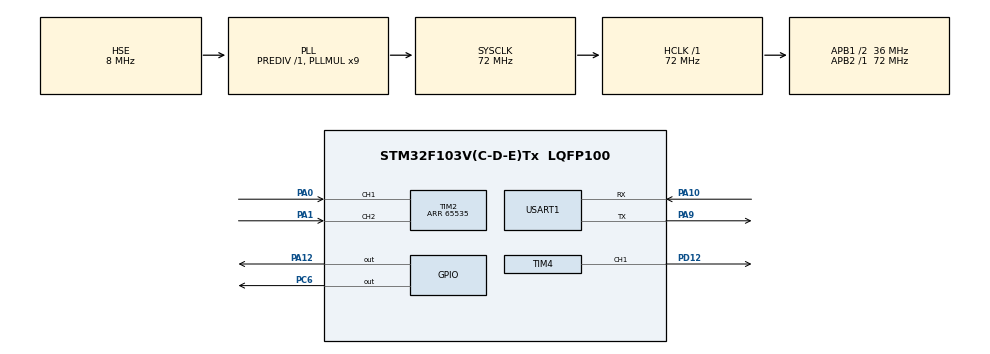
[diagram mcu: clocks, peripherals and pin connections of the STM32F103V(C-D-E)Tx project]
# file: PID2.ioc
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Mcu.Family=STM32F1
Mcu.Name=STM32F103V(C-D-E)Tx
Mcu.Package=LQFP100
NVIC.PriorityGroup=NVIC_PRIORITYGROUP_4
NVIC.TIM3_IRQn=true\:2\:0\:true\:false\:true\:true
NVIC.USART1_IRQn=true\:1\:0\:true\:false\:true\:true
OSC_IN.Mode=HSE-External-Oscillator
OSC_IN.Signal=RCC_OSC_IN
OSC_OUT.Mode=HSE-External-Oscillator
OSC_OUT.Signal=RCC_OSC_OUT
PA0-WKUP.Signal=S_TIM2_CH1_ETR
PA1.Signal=S_TIM2_CH2
PA10.Mode=Asynchronous
PA10.Signal=USART1_RX
PA12.GPIO_ModeDefaultOutputPP=GPIO_MODE_OUTPUT_OD
PA12.GPIO_Speed=GPIO_SPEED_FREQ_HIGH
PA12.PinState=GPIO_PIN_SET
PA12.Signal=GPIO_Output
PA13.Mode=JTAG_5_pins
PA13.Signal=SYS_JTMS-SWDIO
PA14.Mode=JTAG_5_pins
PA14.Signal=SYS_JTCK-SWCLK
PA15.Mode=JTAG_5_pins
PA15.Signal=SYS_JTDI
PA9.Mode=Asynchronous
PA9.Signal=USART1_TX
PB3.Mode=JTAG_5_pins
PB3.Signal=SYS_JTDO-TRACESWO
PB4.Mode=JTAG_5_pins
PB4.Signal=SYS_NJTRST
PC6.GPIO_Speed=GPIO_SPEED_FREQ_HIGH
PC6.PinState=GPIO_PIN_SET
PC6.Signal=GPIO_Output
PD12.Signal=S_TIM4_CH1
ProjectManager.HeapSize=0x200
ProjectManager.StackSize=0x400
ProjectManager.TargetToolchain=EWARM
RCC.AHBFreq_Value=72000000
RCC.APB1CLKDivider=RCC_HCLK_DIV2
RCC.APB1Freq_Value=36000000
RCC.APB1TimFreq_Value=72000000
RCC.APB2Freq_Value=72000000
RCC.APB2TimFreq_Value=72000000
RCC.HCLKFreq_Value=72000000
RCC.PLLMUL=RCC_PLL_MUL9
RCC.PLLSourceVirtual=RCC_PLLSOURCE_HSE
RCC.SYSCLKFreq_VALUE=72000000
RCC.SYSCLKSource=RCC_SYSCLKSOURCE_PLLCLK
RCC.USBFreq_Value=72000000
SH.S_TIM2_CH1_ETR.0=TIM2_CH1,Encoder_Interface
SH.S_TIM2_CH2.0=TIM2_CH2,Encoder_Interface
SH.S_TIM4_CH1.0=TIM4_CH1,PWM Generation1 CH1
TIM2.Period=65535
TIM3.CounterMode=TIM_COUNTERMODE_DOWN
TIM3.Period=59999
TIM3.Prescaler=35
TIM4.Channel-PWM\ Generation1\ CH1=TIM_CHANNEL_1
TIM4.Period=7199
TIM4.Pulse-PWM\ Generation1\ CH1=3600
USART1.VirtualMode=VM_ASYNC
VP_TIM3_VS_ClockSourceINT.Mode=Internal
VP_TIM4_VS_ClockSourceINT.Mode=Internal
board=PID2

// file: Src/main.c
/**
  ******************************************************************************
  * File Name          : main.c
  * Description        : Main program body
  ******************************************************************************
  ** This notice applies to any and all portions of this file
  * that are not between comment pairs USER CODE BEGIN and
  * USER CODE END. Other portions of this file, whether
  * inserted by the user or by software development tools
  * are owned by their respective copyright owners.
  *
  * COPYRIGHT(c) 2017 STMicroelectronics
  *
  * Redistribution and use in source and binary forms, with or without modification,
  * are permitted provided that the following conditions are met:
  *   1. Redistributions of source code must retain the above copyright notice,
  *      this list of conditions and the following disclaimer.
  *   2. Redistributions in binary form must reproduce the above copyright notice,
  *      this list of conditions and the following disclaimer in the documentation
  *      and/or other materials provided with the distribution.
  *   3. Neither the name of STMicroelectronics nor the names of its contributors
  *      may be used to endorse or promote products derived from this software
  *      without specific prior written permission.
  *
  * THIS SOFTWARE IS PROVIDED BY THE COPYRIGHT HOLDERS AND CONTRIBUTORS "AS IS"
  * AND ANY EXPRESS OR IMPLIED WARRANTIES, INCLUDING, BUT NOT LIMITED TO, THE
  * IMPLIED WARRANTIES OF MERCHANTABILITY AND FITNESS FOR A PARTICULAR PURPOSE ARE
  * DISCLAIMED. IN NO EVENT SHALL THE COPYRIGHT HOLDER OR CONTRIBUTORS BE LIABLE
  * FOR ANY DIRECT, INDIRECT, INCIDENTAL, SPECIAL, EXEMPLARY, OR CONSEQUENTIAL
  * DAMAGES (INCLUDING, BUT NOT LIMITED TO, PROCUREMENT OF SUBSTITUTE GOODS OR
  * SERVICES; LOSS OF USE, DATA, OR PROFITS; OR BUSINESS INTERRUPTION) HOWEVER
  * CAUSED AND ON ANY THEORY OF LIABILITY, WHETHER IN CONTRACT, STRICT LIABILITY,
  * OR TORT (INCLUDING NEGLIGENCE OR OTHERWISE) ARISING IN ANY WAY OUT OF THE USE
  * OF THIS SOFTWARE, EVEN IF ADVISED OF THE POSSIBILITY OF SUCH DAMAGE.
  *
  ******************************************************************************
  */

#include "main.h"
#include "stm32f1xx_hal.h"

TIM_HandleTypeDef htim2;
TIM_HandleTypeDef htim3;
TIM_HandleTypeDef htim4;

UART_HandleTypeDef huart1;

/* USER CODE BEGIN PV */
/* Private variables ---------------------------------------------------------*/

/* USER CODE END PV */

void SystemClock_Config(void);
static void MX_GPIO_Init(void);
static void MX_TIM2_Init(void);
static void MX_TIM4_Init(void);
static void MX_USART1_UART_Init(void);
static void MX_TIM3_Init(void);

void HAL_TIM_MspPostInit(TIM_HandleTypeDef *htim);

/* USER CODE BEGIN PFP */
/* Private function prototypes -----------------------------------------------*/

/* USER CODE END PFP */

int main(void)
{

  /* MCU Configuration----------------------------------------------------------*/

  /* Reset of all peripherals, Initializes the Flash interface and the Systick. */
  HAL_Init();

  /* Configure the system clock */
  SystemClock_Config();

  /* Initialize all configured peripherals */
  MX_GPIO_Init();
  MX_TIM2_Init();
  MX_TIM4_Init();
  MX_USART1_UART_Init();
  MX_TIM3_Init();

  /* USER CODE BEGIN 2 */
  HAL_TIM_Encoder_Start(&htim2, TIM_CHANNEL_ALL);//测速定时器
  HAL_TIM_Base_Start_IT(&htim3);//50ms pid 采样中断定时器
  HAL_TIM_PWM_Start(&htim4,TIM_CHANNEL_1);//10k pwm输出
  /* USER CODE END 2 */

  /* Infinite loop */
  while (1)
  {

  }

}

/** System Clock Configuration
*/
void SystemClock_Config(void)
{

  RCC_OscInitTypeDef RCC_OscInitStruct;
  RCC_ClkInitTypeDef RCC_ClkInitStruct;

    /**Initializes the CPU, AHB and APB busses clocks
    */
  RCC_OscInitStruct.OscillatorType = RCC_OSCILLATORTYPE_HSE;
  RCC_OscInitStruct.HSEState = RCC_HSE_ON;
  RCC_OscInitStruct.HSEPredivValue = RCC_HSE_PREDIV_DIV1;
  RCC_OscInitStruct.HSIState = RCC_HSI_ON;
  RCC_OscInitStruct.PLL.PLLState = RCC_PLL_ON;
  RCC_OscInitStruct.PLL.PLLSource = RCC_PLLSOURCE_HSE;
  RCC_OscInitStruct.PLL.PLLMUL = RCC_PLL_MUL9;
  if (HAL_RCC_OscConfig(&RCC_OscInitStruct) != HAL_OK)
  {
    _Error_Handler(__FILE__, __LINE__);
  }

    /**Initializes the CPU, AHB and APB busses clocks
    */
  RCC_ClkInitStruct.ClockType = RCC_CLOCKTYPE_HCLK|RCC_CLOCKTYPE_SYSCLK
                              |RCC_CLOCKTYPE_PCLK1|RCC_CLOCKTYPE_PCLK2;
  RCC_ClkInitStruct.SYSCLKSource = RCC_SYSCLKSOURCE_PLLCLK;
  RCC_ClkInitStruct.AHBCLKDivider = RCC_SYSCLK_DIV1;
  RCC_ClkInitStruct.APB1CLKDivider = RCC_HCLK_DIV2;
  RCC_ClkInitStruct.APB2CLKDivider = RCC_HCLK_DIV1;

  if (HAL_RCC_ClockConfig(&RCC_ClkInitStruct, FLASH_LATENCY_2) != HAL_OK)
  {
    _Error_Handler(__FILE__, __LINE__);
  }

    /**Configure the Systick interrupt time
    */
  HAL_SYSTICK_Config(HAL_RCC_GetHCLKFreq()/1000);

    /**Configure the Systick
    */
  HAL_SYSTICK_CLKSourceConfig(SYSTICK_CLKSOURCE_HCLK);

  /* SysTick_IRQn interrupt configuration */
  HAL_NVIC_SetPriority(SysTick_IRQn, 0, 0);
}

/* TIM2 init function */
static void MX_TIM2_Init(void)
{

  TIM_Encoder_InitTypeDef sConfig;
  TIM_MasterConfigTypeDef sMasterConfig;

  htim2.Instance = TIM2;
  htim2.Init.Prescaler = 0;
  htim2.Init.CounterMode = TIM_COUNTERMODE_UP;
  htim2.Init.Period = 65535;
  htim2.Init.ClockDivision = TIM_CLOCKDIVISION_DIV1;
  htim2.Init.AutoReloadPreload = TIM_AUTORELOAD_PRELOAD_DISABLE;
  sConfig.EncoderMode = TIM_ENCODERMODE_TI1;
  sConfig.IC1Polarity = TIM_ICPOLARITY_RISING;
  sConfig.IC1Selection = TIM_ICSELECTION_DIRECTTI;
  sConfig.IC1Prescaler = TIM_ICPSC_DIV1;
  sConfig.IC1Filter = 0;
  sConfig.IC2Polarity = TIM_ICPOLARITY_RISING;
  sConfig.IC2Selection = TIM_ICSELECTION_DIRECTTI;
  sConfig.IC2Prescaler = TIM_ICPSC_DIV1;
  sConfig.IC2Filter = 0;
  if (HAL_TIM_Encoder_Init(&htim2, &sConfig) != HAL_OK)
  {
    _Error_Handler(__FILE__, __LINE__);
  }

  sMasterConfig.MasterOutputTrigger = TIM_TRGO_RESET;
  sMasterConfig.MasterSlaveMode = TIM_MASTERSLAVEMODE_DISABLE;
  if (HAL_TIMEx_MasterConfigSynchronization(&htim2, &sMasterConfig) != HAL_OK)
  {
    _Error_Handler(__FILE__, __LINE__);
  }

}

/* TIM3 init function */
static void MX_TIM3_Init(void)
{

  TIM_ClockConfigTypeDef sClockSourceConfig;
  TIM_MasterConfigTypeDef sMasterConfig;

  htim3.Instance = TIM3;
  htim3.Init.Prescaler = 35;
  htim3.Init.CounterMode = TIM_COUNTERMODE_DOWN;
  htim3.Init.Period = 59999;
  htim3.Init.ClockDivision = TIM_CLOCKDIVISION_DIV1;
  htim3.Init.AutoReloadPreload = TIM_AUTORELOAD_PRELOAD_DISABLE;
  if (HAL_TIM_Base_Init(&htim3) != HAL_OK)
  {
    _Error_Handler(__FILE__, __LINE__);
  }

  sClockSourceConfig.ClockSource = TIM_CLOCKSOURCE_INTERNAL;
  if (HAL_TIM_ConfigClockSource(&htim3, &sClockSourceConfig) != HAL_OK)
  {
    _Error_Handler(__FILE__, __LINE__);
  }

  sMasterConfig.MasterOutputTrigger = TIM_TRGO_RESET;
  sMasterConfig.MasterSlaveMode = TIM_MASTERSLAVEMODE_DISABLE;
  if (HAL_TIMEx_MasterConfigSynchronization(&htim3, &sMasterConfig) != HAL_OK)
  {
    _Error_Handler(__FILE__, __LINE__);
  }

}

/* TIM4 init function */
static void MX_TIM4_Init(void)
{

  TIM_ClockConfigTypeDef sClockSourceConfig;
  TIM_MasterConfigTypeDef sMasterConfig;
  TIM_OC_InitTypeDef sConfigOC;

  htim4.Instance = TIM4;
  htim4.Init.Prescaler = 0;
  htim4.Init.CounterMode = TIM_COUNTERMODE_UP;
  htim4.Init.Period = 7199;
  htim4.Init.ClockDivision = TIM_CLOCKDIVISION_DIV1;
  htim4.Init.AutoReloadPreload = TIM_AUTORELOAD_PRELOAD_DISABLE;
  if (HAL_TIM_Base_Init(&htim4) != HAL_OK)
  {
    _Error_Handler(__FILE__, __LINE__);
  }

  sClockSourceConfig.ClockSource = TIM_CLOCKSOURCE_INTERNAL;
  if (HAL_TIM_ConfigClockSource(&htim4, &sClockSourceConfig) != HAL_OK)
  {
    _Error_Handler(__FILE__, __LINE__);
  }

  if (HAL_TIM_PWM_Init(&htim4) != HAL_OK)
  {
    _Error_Handler(__FILE__, __LINE__);
  }

  sMasterConfig.MasterOutputTrigger = TIM_TRGO_RESET;
  sMasterConfig.MasterSlaveMode = TIM_MASTERSLAVEMODE_DISABLE;
  if (HAL_TIMEx_MasterConfigSynchronization(&htim4, &sMasterConfig) != HAL_OK)
  {
    _Error_Handler(__FILE__, __LINE__);
  }

  sConfigOC.OCMode = TIM_OCMODE_PWM1;
  sConfigOC.Pulse = 3600;
  sConfigOC.OCPolarity = TIM_OCPOLARITY_HIGH;
  sConfigOC.OCFastMode = TIM_OCFAST_DISABLE;
  if (HAL_TIM_PWM_ConfigChannel(&htim4, &sConfigOC, TIM_CHANNEL_1) != HAL_OK)
  {
    _Error_Handler(__FILE__, __LINE__);
  }

  HAL_TIM_MspPostInit(&htim4);

}

/* USART1 init function */
static void MX_USART1_UART_Init(void)
{

  huart1.Instance = USART1;
  huart1.Init.BaudRate = 115200;
  huart1.Init.WordLength = UART_WORDLENGTH_8B;
  huart1.Init.StopBits = UART_STOPBITS_1;
  huart1.Init.Parity = UART_PARITY_NONE;
  huart1.Init.Mode = UART_MODE_TX_RX;
  huart1.Init.HwFlowCtl = UART_HWCONTROL_NONE;
  huart1.Init.OverSampling = UART_OVERSAMPLING_16;
  if (HAL_UART_Init(&huart1) != HAL_OK)
  {
    _Error_Handler(__FILE__, __LINE__);
  }

}

/** Configure pins as
        * Analog
        * Input
        * Output
        * EVENT_OUT
        * EXTI
*/
static void MX_GPIO_Init(void)
{

  GPIO_InitTypeDef GPIO_InitStruct;

  /* GPIO Ports Clock Enable */
  __HAL_RCC_GPIOA_CLK_ENABLE();
  __HAL_RCC_GPIOD_CLK_ENABLE();
  __HAL_RCC_GPIOC_CLK_ENABLE();
  __HAL_RCC_GPIOB_CLK_ENABLE();

  /*Configure GPIO pin Output Level */
  HAL_GPIO_WritePin(GPIOC, GPIO_PIN_6, GPIO_PIN_SET);

  /*Configure GPIO pin Output Level */
  HAL_GPIO_WritePin(GPIOA, GPIO_PIN_12, GPIO_PIN_SET);

  /*Configure GPIO pin : PC6 */
  GPIO_InitStruct.Pin = GPIO_PIN_6;
  GPIO_InitStruct.Mode = GPIO_MODE_OUTPUT_PP;
  GPIO_InitStruct.Speed = GPIO_SPEED_FREQ_HIGH;
  HAL_GPIO_Init(GPIOC, &GPIO_InitStruct);

  /*Configure GPIO pin : PA12 */
  GPIO_InitStruct.Pin = GPIO_PIN_12;
  GPIO_InitStruct.Mode = GPIO_MODE_OUTPUT_OD;
  GPIO_InitStruct.Speed = GPIO_SPEED_FREQ_HIGH;
  HAL_GPIO_Init(GPIOA, &GPIO_InitStruct);

}

void _Error_Handler(char * file, int line)
{
  while(1)
  {
  }
}

/************************ (C) COPYRIGHT STMicroelectronics *****END OF FILE****/
